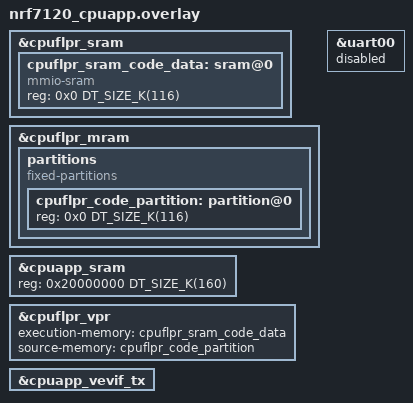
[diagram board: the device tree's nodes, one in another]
/*
 * Copyright (c) 2025 Nordic Semiconductor
 * SPDX-License-Identifier: LicenseRef-Nordic-5-Clause
 */

&cpuflpr_sram {
	cpuflpr_sram_code_data: sram@0 {
		compatible = "mmio-sram";
		reg = <0x0 DT_SIZE_K(116)>;
		#address-cells = <1>;
		#size-cells = <1>;
	};
};

&cpuflpr_mram {
	partitions {
		compatible = "fixed-partitions";
		#address-cells = <1>;
		#size-cells = <1>;

		cpuflpr_code_partition: partition@0 {
			reg = <0x0 DT_SIZE_K(116)>;
		};
	};
};

&uart00 {
	status = "reserved";
};

&cpuapp_sram {
	reg = <0x20000000 DT_SIZE_K(160)>;
	ranges = <0x0 0x20000000 0x28000>;
};

&cpuflpr_vpr {
	execution-memory = <&cpuflpr_sram_code_data>;
	source-memory = <&cpuflpr_code_partition>;
};

&cpuapp_vevif_tx {
	status = "okay";
};
